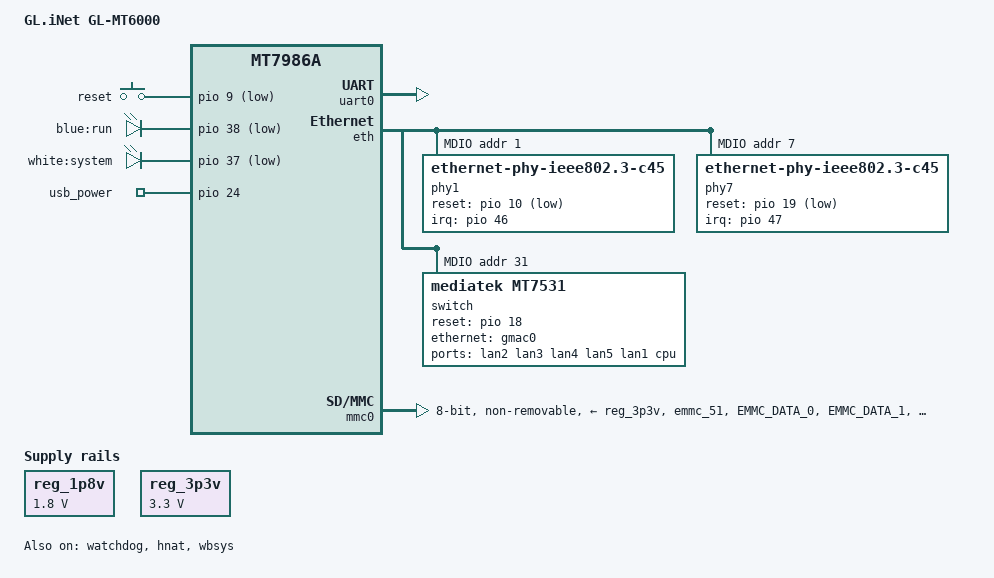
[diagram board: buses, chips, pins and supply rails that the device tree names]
/dts-v1/;
#include "mt7986a.dtsi"
#include "mt7986a-pinctrl.dtsi"
#include <dt-bindings/input/input.h>
#include <dt-bindings/gpio/gpio.h>

/ {
	model = "GL.iNet GL-MT6000";
	compatible = "glinet,gl-mt6000","mediatek,mt7986a";

	aliases {
		serial0 = &uart0;
		label-mac-device = &gmac1;
		led-boot = &led_white;
		led-failsafe = &led_white;
		led-running = &led_blue;
		led-upgrade = &led_blue;
	};

	chosen {
		bootargs = "console=ttyS0,115200n1 loglevel=8  \
				earlycon=uart8250,mmio32,0x11002000 \
				root=PARTLABEL=rootfs rootwait";
	};

	gpio-keys {
		compatible = "gpio-keys";

		reset {
			label = "reset";
			linux,code = <KEY_RESTART>;
			gpios = <&pio 9 GPIO_ACTIVE_LOW>;
		};
	};

	leds {
		compatible = "gpio-leds";

		led_blue: led@0 {
			label = "blue:run";
			gpios = <&pio 38 GPIO_ACTIVE_LOW>;
			default-state = "on";
		};

		led_white: led@1 {
			label = "white:system";
			gpios = <&pio 37 GPIO_ACTIVE_LOW>;
		};
	};

	reg_1p8v: regulator-1p8v {
		compatible = "regulator-fixed";
		regulator-name = "fixed-1.8V";
		regulator-min-microvolt = <1800000>;
		regulator-max-microvolt = <1800000>;
		regulator-boot-on;
		regulator-always-on;
	};

	reg_3p3v: regulator-3p3v {
		compatible = "regulator-fixed";
		regulator-name = "fixed-3.3V";
		regulator-min-microvolt = <3300000>;
		regulator-max-microvolt = <3300000>;
		regulator-boot-on;
		regulator-always-on;
	};

	gpio-export {
		compatible = "gpio-export";

		usb_power {
			gpio-export,name = "usb_power";
			gpio-export,output = <1>;
			gpios = <&pio 24 GPIO_ACTIVE_HIGH>;
		};
	};
};

&uart0 {
	status = "okay";
};

&watchdog {
	status = "okay";
};

&eth {
	status = "okay";

	gmac0: mac@0 {
		compatible = "mediatek,eth-mac";
		reg = <0>;
		phy-mode = "2500base-x";

		fixed-link {
			speed = <2500>;
			full-duplex;
			pause;
		};
	};

	gmac1: mac@1 {
		compatible = "mediatek,eth-mac";
		reg = <1>;
		phy-mode = "2500base-x";
		phy-handle = <&phy1>;
	};

	mdio: mdio-bus {
		#address-cells = <1>;
		#size-cells = <0>;

		phy1: phy@1 {
			compatible = "ethernet-phy-ieee802.3-c45";
			reg = <1>;
			reset-assert-us = <100000>;
			reset-deassert-us = <100000>;
			reset-gpios = <&pio 10 GPIO_ACTIVE_LOW>;
			interrupt-parent = <&pio>;
			interrupts = <46 IRQ_TYPE_LEVEL_LOW>;
			realtek,aldps-enable;
		};

		phy7: phy@7 {
			compatible = "ethernet-phy-ieee802.3-c45";
			reg = <7>;
			reset-assert-us = <100000>;
			reset-deassert-us = <100000>;
			reset-gpios = <&pio 19 GPIO_ACTIVE_LOW>;
			interrupt-parent = <&pio>;
			interrupts = <47 IRQ_TYPE_LEVEL_LOW>;
			realtek,aldps-enable;
		};

		switch@0 {
			compatible = "mediatek,mt7531";
			reg = <31>;
			reset-gpios = <&pio 18 GPIO_ACTIVE_HIGH>;

			ports {
				#address-cells = <1>;
				#size-cells = <0>;

				port@0 {
					reg = <0>;
					label = "lan2";
				};

				port@1 {
					reg = <1>;
					label = "lan3";
				};

				port@2 {
					reg = <2>;
					label = "lan4";
				};

				port@3 {
					reg = <3>;
					label = "lan5";
				};

				port@5 {
					reg = <5>;
					label = "lan1";
					phy-mode = "2500base-x";
					phy-handle = <&phy7>;
				};

				port@6 {
					reg = <6>;
					label = "cpu";
					ethernet = <&gmac0>;
					phy-mode = "2500base-x";

					fixed-link {
						speed = <2500>;
						full-duplex;
						pause;
					};
				};
			};
		};
	};
};

&hnat {
	mtketh-wan = "eth1";
	mtketh-lan = "lan";
	mtketh-max-gmac = <2>;
	status = "okay";
};

&mmc0 {
	pinctrl-names = "default", "state_uhs";
	pinctrl-0 = <&mmc0_pins_default>;
	pinctrl-1 = <&mmc0_pins_uhs>;
	bus-width = <8>;
	max-frequency = <200000000>;
	cap-mmc-highspeed;
	mmc-hs200-1_8v;
	mmc-hs400-1_8v;
	hs400-ds-delay = <0x14014>;
	vmmc-supply = <&reg_3p3v>;
	vqmmc-supply = <&reg_1p8v>;
	non-removable;
	no-sd;
	no-sdio;
	status = "okay";
};

&wbsys {
	status = "okay";
};

&pio {
	mmc0_pins_default: mmc0-pins-50-to-61-default {
		mux {
			function = "flash";
			groups = "emmc_51";
		};
		conf-cmd-dat {
			pins = "EMMC_DATA_0", "EMMC_DATA_1", "EMMC_DATA_2",
			       "EMMC_DATA_3", "EMMC_DATA_4", "EMMC_DATA_5",
			       "EMMC_DATA_6", "EMMC_DATA_7", "EMMC_CMD";
			input-enable;
			drive-strength = <MTK_DRIVE_4mA>;
			mediatek,pull-up-adv = <1>;	/* pull-up 10K */
		};
		conf-clk {
			pins = "EMMC_CK";
			drive-strength = <MTK_DRIVE_6mA>;
			mediatek,pull-down-adv = <2>;	/* pull-down 50K */
		};
		conf-ds {
			pins = "EMMC_DSL";
			mediatek,pull-down-adv = <2>;	/* pull-down 50K */
		};
		conf-rst {
			pins = "EMMC_RSTB";
			drive-strength = <MTK_DRIVE_4mA>;
			mediatek,pull-up-adv = <1>;	/* pull-up 10K */
		};
	};

	mmc0_pins_uhs: mmc0-pins-50-to-61-uhs {
		mux {
			function = "flash";
			groups = "emmc_51";
		};
		conf-cmd-dat {
			pins = "EMMC_DATA_0", "EMMC_DATA_1", "EMMC_DATA_2",
			       "EMMC_DATA_3", "EMMC_DATA_4", "EMMC_DATA_5",
			       "EMMC_DATA_6", "EMMC_DATA_7", "EMMC_CMD";
			input-enable;
			drive-strength = <MTK_DRIVE_4mA>;
			mediatek,pull-up-adv = <1>;	/* pull-up 10K */
		};
		conf-clk {
			pins = "EMMC_CK";
			drive-strength = <MTK_DRIVE_6mA>;
			mediatek,pull-down-adv = <2>;	/* pull-down 50K */
		};
		conf-ds {
			pins = "EMMC_DSL";
			mediatek,pull-down-adv = <2>;	/* pull-down 50K */
		};
		conf-rst {
			pins = "EMMC_RSTB";
			drive-strength = <MTK_DRIVE_4mA>;
			mediatek,pull-up-adv = <1>;	/* pull-up 10K */
		};
	};
};
